# STM32WBA52 register map
File version: 0.1
CPU: CM33 r0p1, little endian, MPU, FPU, 4 interrupt priority bits
Registers are 32-bit, read-write, reset 0x0 unless marked. A register's access mark holds for its fields unless they carry their own. Offsets are from the block's base; [hi:lo] are bit positions.

## GTZC1_TZIC
Base 0x40032800
Same registers: SEC_GTZC1_TZIC 0x50032800
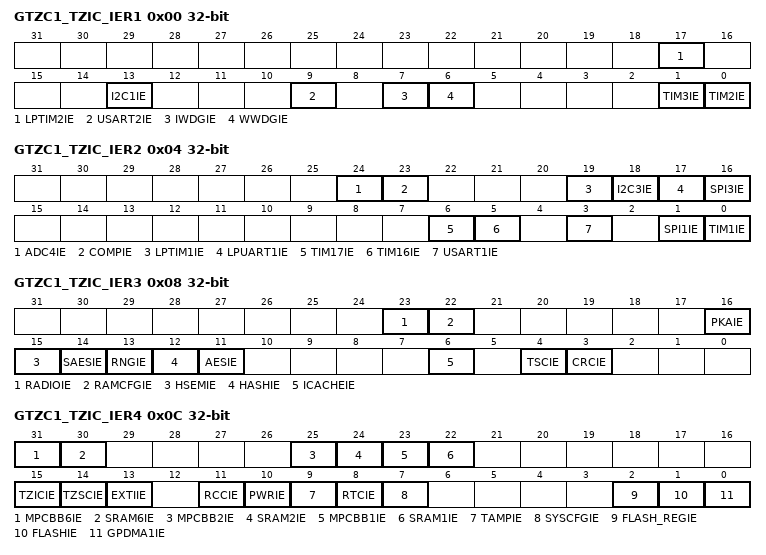
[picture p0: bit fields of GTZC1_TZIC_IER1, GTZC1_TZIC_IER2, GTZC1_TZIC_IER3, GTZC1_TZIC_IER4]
0x00 GTZC1_TZIC_IER1 — TZIC interrupt enable register 1
  [all] fields
    0=interrupt disabled; 1=interrupt enabled
  [17] LPTIM2IE — illegal access interrupt enable for LPTIM2
  [13] I2C1IE — illegal access interrupt enable for I2C1
  [9] USART2IE — illegal access interrupt enable for USART2
  [7] IWDGIE — illegal access interrupt enable for IWDG
  [6] WWDGIE — illegal access interrupt enable for WWDG
  [1] TIM3IE — illegal access interrupt enable for TIM3
  [0] TIM2IE — illegal access interrupt enable for TIM2
0x04 GTZC1_TZIC_IER2 — GTZC1 TZIC interrupt enable register 2
  [all] fields
    0=interrupt disabled; 1=interrupt enabled
  [24] ADC4IE — illegal access interrupt enable for ADC4
  [23] COMPIE — illegal access interrupt enable for COMP Note that bit 23 is reserved on sales type STM32WBA52.
  [19] LPTIM1IE — illegal access interrupt enable for LPTIM1
  [18] I2C3IE — illegal access interrupt enable for I2C3
  [17] LPUART1IE — illegal access interrupt enable for LPUART1
  [16] SPI3IE — illegal access interrupt enable for SPI3
  [6] TIM17IE — illegal access interrupt enable for TIM17
  [5] TIM16IE — illegal access interrupt enable for TIM16
  [3] USART1IE — illegal access interrupt enable for USART1
  [1] SPI1IE — illegal access interrupt enable for SPI1
  [0] TIM1IE — illegal access interrupt enable for TIM1
0x08 GTZC1_TZIC_IER3 — GTZC1 TZIC interrupt enable register 3
  [all] fields
    0=interrupt disabled; 1=interrupt enabled
  [23] RADIOIE — illegal access interrupt enable for 2.4 GHz RADIO
  [22] RAMCFGIE — illegal access interrupt enable for RAMCFG
  [16] PKAIE — illegal access interrupt enable for PKA
  [15] HSEMIE — illegal access interrupt enable for HSEM
  [14] SAESIE — illegal access interrupt enable for SAES
  [13] RNGIE — illegal access interrupt enable for RNG
  [12] HASHIE — illegal access interrupt enable for HASH
  [11] AESIE — illegal access interrupt enable for AES
  [6] ICACHEIE — illegal access interrupt enable for ICACHE registers
  [4] TSCIE — illegal access interrupt enable for TSC
  [3] CRCIE — illegal access interrupt enable for CRC
0x0C GTZC1_TZIC_IER4 — GTZC1 TZIC interrupt enable register 4
  [all] fields
    0=interrupt disabled; 1=interrupt enabled
  [31] MPCBB6IE — illegal access interrupt enable for MPCBB6
  [30] SRAM6IE — illegal access interrupt enable for 2.4GHz RXTXRAM memory
  [25] MPCBB2IE — illegal access interrupt enable for MPCBB2
  [24] SRAM2IE — illegal access interrupt enable for SRAM2 memory
  [23] MPCBB1IE — illegal access interrupt enable for MPCBB1
  [22] SRAM1IE — illegal access interrupt enable for SRAM1 memory
  [15] TZICIE — illegal access interrupt enable for GTZC1 TZIC
  [14] TZSCIE — illegal access interrupt enable for GTZC1 TZSC
  [13] EXTIIE — illegal access interrupt enable for EXTI
  [11] RCCIE — illegal access interrupt enable for RCC
  [10] PWRIE — illegal access interrupt enable for PWR
  [9] TAMPIE — illegal access interrupt enable for TAMP
  [8] RTCIE — illegal access interrupt enable for RTC
  [7] SYSCFGIE — illegal access interrupt enable for SYSCFG
  [2] FLASH_REGIE — illegal access interrupt enable for FLASH interface
  [1] FLASHIE — illegal access interrupt enable for FLASH memory
  [0] GPDMA1IE — illegal access interrupt enable for GPDMA1
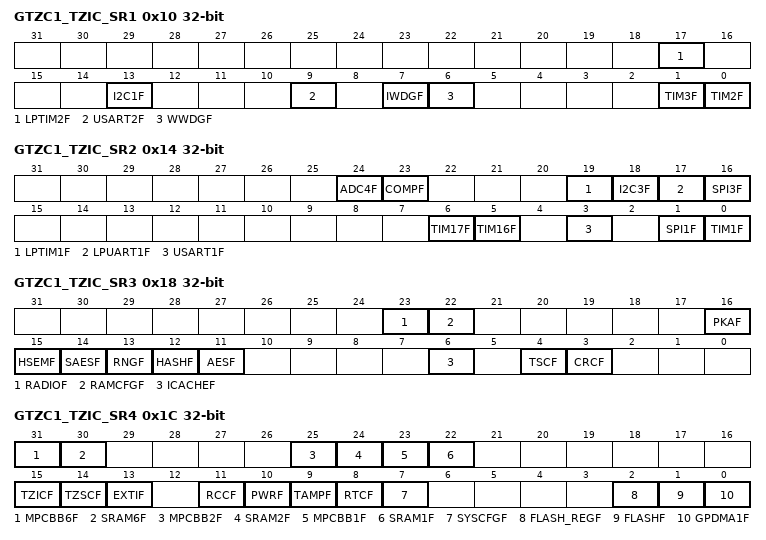
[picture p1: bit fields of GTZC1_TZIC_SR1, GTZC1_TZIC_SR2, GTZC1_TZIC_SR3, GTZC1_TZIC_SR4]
0x10 GTZC1_TZIC_SR1 ro — TZIC status register 1
  [all] fields
    0=no illegal access event; 1=illegal access event
  [17] LPTIM2F — illegal access flag for LPTIM2
  [13] I2C1F — illegal access flag for I2C1
  [9] USART2F — illegal access flag for USART2
  [7] IWDGF — illegal access flag for IWDG
  [6] WWDGF — illegal access flag for WWDG
  [1] TIM3F — illegal access flag for TIM3
  [0] TIM2F — illegal access flag for TIM2
0x14 GTZC1_TZIC_SR2 ro — TZIC status register 2
  [24] ADC4F
  [23] COMPF
  [19] LPTIM1F
  [18] I2C3F
  [17] LPUART1F
  [16] SPI3F
  [6] TIM17F — illegal access flag for TIM7
  [5] TIM16F — illegal access flag for TIM6
  [3] USART1F — illegal access flag for USART1
  [1] SPI1F — illegal access flag for SPI1
  [0] TIM1F — illegal access flag for TIM1
0x18 GTZC1_TZIC_SR3 ro — TZIC status register 3
  [23] RADIOF — illegal access flag for 2.4 GHz RADIO
  [22] RAMCFGF — illegal access flag for RAMCFG
  [16] PKAF — illegal access flag for PKA
  [15] HSEMF — illegal access flag for HSEM
  [14] SAESF — illegal access flag for SAES
  [13] RNGF — illegal access flag for RNG
  [12] HASHF — illegal access flag for HASH
  [11] AESF — illegal access flag for AES
  [6] ICACHEF — illegal access flag for ICACHE registers
  [4] TSCF — illegal access flag for TSC
  [3] CRCF — illegal access flag for CRC
0x1C GTZC1_TZIC_SR4 ro — GTZC1 TZIC status register 4
  [all] fields
    0=no illegal access event; 1=illegal access event
  [31] MPCBB6F — illegal access flag for MPCBB6
  [30] SRAM6F — illegal access flag for 2.4 GHZ RADIO RXTXRAM memory
  [25] MPCBB2F — illegal access flag for MPCBB2
  [24] SRAM2F — illegal access flag for SRAM2 memory
  [23] MPCBB1F — illegal access flag for MPCBB1
  [22] SRAM1F — illegal access flag for SRAM1 memory
  [15] TZICF — illegal access flag for GTZC1 TZIC
  [14] TZSCF — illegal access flag for GTZC1 TZSC
  [13] EXTIF — illegal access flag for EXTI
  [11] RCCF — illegal access flag for RCC
  [10] PWRF — illegal access flag for PWR
  [9] TAMPF — illegal access flag for TAMP
  [8] RTCF — illegal access flag for RTC
  [7] SYSCFGF — illegal access flag for SYSCFG
  [2] FLASH_REGF — illegal access flag for FLASH interface
  [1] FLASHF — illegal access flag for FLASH memory
  [0] GPDMA1F — illegal access flag for GPDMA1
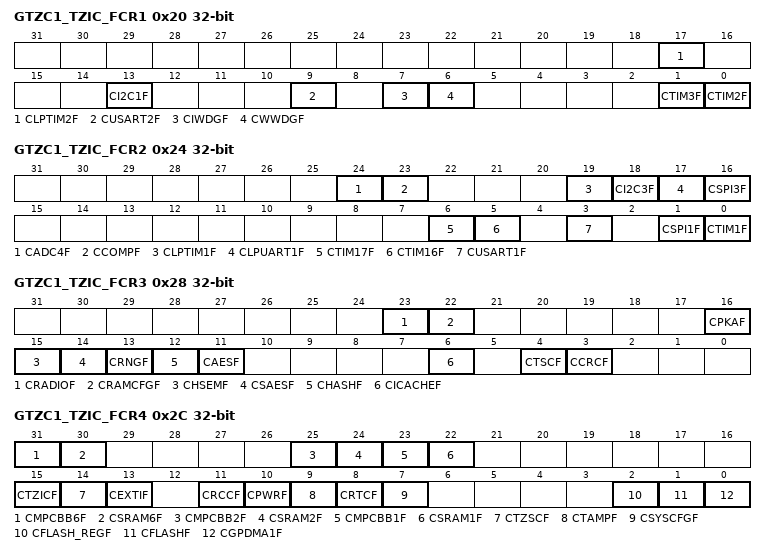
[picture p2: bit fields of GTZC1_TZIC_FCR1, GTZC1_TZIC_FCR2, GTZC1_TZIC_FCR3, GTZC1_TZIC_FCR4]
0x20 GTZC1_TZIC_FCR1 wo — TZIC flag clear register 1
  [17] CLPTIM2F — clear the illegal access flag for LPTIM2
  [13] CI2C1F — clear the illegal access flag for I2C1
  [9] CUSART2F — clear the illegal access flag for USART2
  [7] CIWDGF — clear the illegal access flag for IWDG
  [6] CWWDGF — clear the illegal access flag for WWDG
  [1] CTIM3F — clear the illegal access flag for TIM3
  [0] CTIM2F — clear the illegal access flag for TIM2
0x24 GTZC1_TZIC_FCR2 wo — TZIC flag clear register 2
  [24] CADC4F — clear the illegal access flag for ADC4
  [23] CCOMPF — iclear the illegal access flag for COMP
  [19] CLPTIM1F — clear the illegal access flag for LPTIM1
  [18] CI2C3F — clear the illegal access flag for I2C3
  [17] CLPUART1F — clear the illegal access flag for LPUART1
  [16] CSPI3F — clear the illegal access flag for SPI3
  [6] CTIM17F — clear the illegal access flag for TIM7
  [5] CTIM16F — clear the illegal access flag for TIM6
  [3] CUSART1F — clear the illegal access flag for USART1
  [1] CSPI1F — clear the illegal access flag for SPI1
  [0] CTIM1F — clear the illegal access flag for TIM1
0x28 GTZC1_TZIC_FCR3 wo — TZIC flag clear register 3
  [23] CRADIOF — clear the illegal access flag for 2.4 GHz RADIO
  [22] CRAMCFGF — clear the illegal access flag for RAMCFG
  [16] CPKAF — clear the illegal access flag for PKA
  [15] CHSEMF — clear the illegal access flag for HSEM
  [14] CSAESF — clear the illegal access flag for SAES
  [13] CRNGF — clear the illegal access flag for RNG
  [12] CHASHF — clear the illegal access flag for HASH
  [11] CAESF — clear the illegal access flag for AES
  [6] CICACHEF — clear the illegal access flag for ICACHE registers
  [4] CTSCF — clear the illegal access flag for TSC
  [3] CCRCF — clear the illegal access flag for CRC
0x2C GTZC1_TZIC_FCR4 wo — GTZC1 TZIC flag clear register 4
  [all] fields
    0=no action; 1=status flag cleared
  [31] CMPCBB6F — clear the illegal access flag for MPCBB6
  [30] CSRAM6F — clear the illegal access flag for 2.4 GHz RADIO RXTXRAM memory
  [25] CMPCBB2F — clear the illegal access flag for MPCBB2
  [24] CSRAM2F — clear the illegal access flag for SRAM2 memory
  [23] CMPCBB1F — clear the illegal access flag for MPCBB1
  [22] CSRAM1F — clear the illegal access flag for SRAM1 memory
  [15] CTZICF — clear the illegal access flag for GTZC1 TZIC
  [14] CTZSCF — clear the illegal access flag for GTZC1 TZSC
  [13] CEXTIF — clear the illegal access flag for EXTI
  [11] CRCCF — clear the illegal access flag for RCC
  [10] CPWRF — clear the illegal access flag for PWR
  [9] CTAMPF — clear the illegal access flag for TAMP
  [8] CRTCF — clear the illegal access flag for RTC
  [7] CSYSCFGF — clear the illegal access flag for SYSCFG
  [2] CFLASH_REGF — clear the illegal access flag for FLASH interface
  [1] CFLASHF — clear the illegal access flag for FLASH memory
  [0] CGPDMA1F — clear the illegal access flag for GPDMA1
